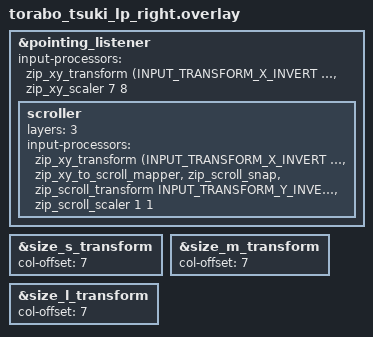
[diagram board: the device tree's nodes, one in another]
#define TORABO_TSUKI_LP_RIGHT 1
#define TORABO_TSUKI_LP_MATRIX_COL_OFFSET 7

#include "torabo_tsuki_lp.dtsi"
#include <input/processors.dtsi>
#include <dt-bindings/zmk/input_transform.h>
#include <scroll-snap.dtsi>

&pointing_listener {
    /* Cursor sensitivity: 7/8 (0.875x) via software scaler so scroll can stay independent.
     * CPI is left at the PAW3222 default (no res-cpi) because a sensor CPI change would
     * scale both cursor and scroll together. */
    input-processors =
        <&zip_xy_transform (INPUT_TRANSFORM_X_INVERT | INPUT_TRANSFORM_Y_INVERT)>,
        <&zip_xy_scaler 7 8>;

    /* Layer 3: XY -> scroll, then axis-snap (kot149/zmk-scroll-snap) to reduce diagonals.
     * Cursor path above is unchanged. Vertical wheel invert is scroll-only. */
    scroller {
        layers = <3>;
        input-processors =
            <&zip_xy_transform (INPUT_TRANSFORM_X_INVERT | INPUT_TRANSFORM_Y_INVERT)>,
            <&zip_xy_to_scroll_mapper>,
            <&zip_scroll_snap>,
            <&zip_scroll_transform INPUT_TRANSFORM_Y_INVERT>,
            <&zip_scroll_scaler 1 1>;
    };
};

&size_s_transform {
    col-offset = <7>;
};

&size_m_transform {
    col-offset = <7>;
};

&size_l_transform {
    col-offset = <7>;
};
